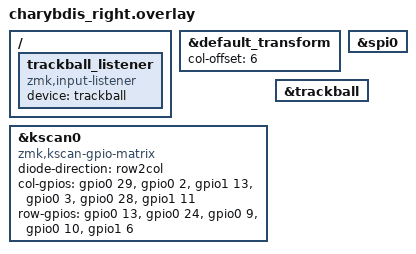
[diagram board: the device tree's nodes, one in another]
#include "charybdis.dtsi"
#include "charybdis_pmw3610.dtsi"

// The matrix transform is 6 columns over because the left half is 6 columns wide.
&default_transform {
	col-offset = <6>;
};

&kscan0 {
    compatible = "zmk,kscan-gpio-matrix";
    diode-direction = "row2col";

    /* 列引脚 (col-gpios) */
    /* 从左到右: 0.29, 0.02, 1.13, 0.03, 0.28, 1.11 */
    col-gpios
        = <&gpio0 29 (GPIO_ACTIVE_HIGH | GPIO_PULL_DOWN)>  // 物理引脚 P0.29
        , <&gpio0 2  (GPIO_ACTIVE_HIGH | GPIO_PULL_DOWN)>  // 物理引脚 P0.02
        , <&gpio1 13 (GPIO_ACTIVE_HIGH | GPIO_PULL_DOWN)>  // 物理引脚 P1.13
        , <&gpio0 3  (GPIO_ACTIVE_HIGH | GPIO_PULL_DOWN)>  // 物理引脚 P0.03
        , <&gpio0 28 (GPIO_ACTIVE_HIGH | GPIO_PULL_DOWN)>  // 物理引脚 P0.28
        , <&gpio1 11 (GPIO_ACTIVE_HIGH | GPIO_PULL_DOWN)>  // 物理引脚 P1.11
        ;

    /* 行引脚 (row-gpios) */
    /* 0.13, 0.24, 0.09, 0.10, 1.06 */
    row-gpios
        = <&gpio0 13 GPIO_ACTIVE_HIGH> // 物理引脚 P0.13
        , <&gpio0 24 GPIO_ACTIVE_HIGH> // 物理引脚 P0.24
        , <&gpio0 9  GPIO_ACTIVE_HIGH> // 物理引脚 P0.09
        , <&gpio0 10 GPIO_ACTIVE_HIGH> // 物理引脚 P0.10
        , <&gpio1 6  GPIO_ACTIVE_HIGH> // 物理引脚 P1.06
        ;
};

&spi0 {
    status = "okay";
};

&trackball {
    status = "okay";
};

// https://github.com/badjeff/zmk-pmw3610-driver
/ {
  trackball_listener {
    compatible = "zmk,input-listener";
    device = <&trackball>;
  };
};



